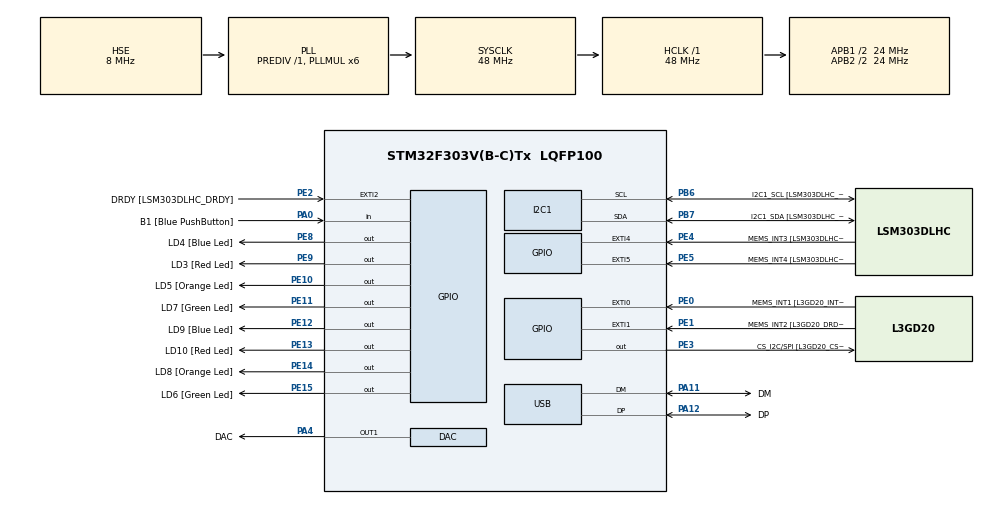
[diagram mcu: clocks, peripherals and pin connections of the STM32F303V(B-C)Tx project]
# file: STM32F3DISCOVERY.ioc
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ADC1.Channel-0\#ChannelRegularConversion=ADC_CHANNEL_TEMPSENSOR
ADC1.ClockPrescaler=ADC_CLOCK_SYNC_PCLK_DIV4
ADC1.NbrOfConversionFlag=1
ADC1.Offset-0\#ChannelRegularConversion=0
ADC1.OffsetNumber-0\#ChannelRegularConversion=ADC_OFFSET_NONE
ADC1.Overrun=ADC_OVR_DATA_OVERWRITTEN
ADC1.Rank-0\#ChannelRegularConversion=1
ADC1.SamplingTime-0\#ChannelRegularConversion=ADC_SAMPLETIME_1CYCLE_5
ADC1.master=1
FREERTOS.Tasks01=defaultTask,0,256,StartDefaultTask,Default
Mcu.Family=STM32F3
Mcu.Name=STM32F303V(B-C)Tx
Mcu.Package=LQFP100
NVIC.PriorityGroup=NVIC_PRIORITYGROUP_4
NVIC.TIM1_UP_TIM16_IRQn=true\:0\:0\:false\:false\:true\:false
NVIC.TimeBase=TIM1_UP_TIM16_IRQn
NVIC.TimeBaseIP=TIM1
NVIC.USB_LP_CAN_RX0_IRQn=true\:0\:0\:false\:false\:true\:false
PA0.GPIO_Label=B1 [Blue PushButton]
PA0.GPIO_Mode=GPIO_MODE_INPUT
PA0.GPIO_PuPd=GPIO_NOPULL
PA0.Signal=GPIO_Input
PA11.GPIO_Label=DM
PA11.Mode=Device
PA11.Signal=USB_DM
PA12.GPIO_Label=DP
PA12.Mode=Device
PA12.Signal=USB_DP
PA13.GPIO_Label=SWDIO
PA13.Mode=Serial_Wire
PA13.Signal=SYS_JTMS-SWDIO
PA14.GPIO_Label=SWCLK
PA14.Mode=Serial_Wire
PA14.Signal=SYS_JTCK-SWCLK
PA4.GPIO_Label=DAC
PA4.Signal=COMP_DAC1_group
PA5.GPIO_Label=SPI1_SCK [L3GD20_SCL/SPC]
PA5.GPIO_Mode=GPIO_MODE_AF_PP
PA5.GPIO_PuPd=GPIO_NOPULL
PA5.GPIO_Speed=GPIO_SPEED_FREQ_LOW
PA5.Signal=SPI1_SCK
PA6.GPIO_Label=SPI1_MISO [L3GD20_SA0/SDO]
PA6.GPIO_Mode=GPIO_MODE_AF_PP
PA6.GPIO_PuPd=GPIO_NOPULL
PA6.GPIO_Speed=GPIO_SPEED_FREQ_LOW
PA6.Signal=SPI1_MISO
PA7.GPIO_Label=SPI1_MISO [L3GD20_SDA/SDI/SDO]
PA7.GPIO_Mode=GPIO_MODE_AF_PP
PA7.GPIO_PuPd=GPIO_NOPULL
PA7.GPIO_Speed=GPIO_SPEED_FREQ_LOW
PA7.Signal=SPI1_MOSI
PB3.GPIO_Label=SWO
PB3.Signal=SYS_JTDO-TRACESWO
PB6.GPIO_FM6=__NULL
PB6.GPIO_Label=I2C1_SCL [LSM303DLHC_SCL]
PB6.GPIO_Mode=GPIO_MODE_AF_OD
PB6.GPIO_PuPd=GPIO_NOPULL
PB6.GPIO_Speed=GPIO_SPEED_FREQ_LOW
PB6.Mode=I2C
PB6.Signal=I2C1_SCL
PB7.GPIO_FM7=__NULL
PB7.GPIO_Label=I2C1_SDA [LSM303DLHC_SDA]
PB7.GPIO_Mode=GPIO_MODE_AF_OD
PB7.GPIO_PuPd=GPIO_NOPULL
PB7.GPIO_Speed=GPIO_SPEED_FREQ_LOW
PB7.Mode=I2C
PB7.Signal=I2C1_SDA
PC14-OSC32_IN.GPIO_Label=OSC32_IN
PC14-OSC32_IN.Mode=LSE-External-Oscillator
PC14-OSC32_IN.Signal=RCC_OSC32_IN
PC15-OSC32_OUT.GPIO_Label=OSC32_OUT
PC15-OSC32_OUT.Mode=LSE-External-Oscillator
PC15-OSC32_OUT.Signal=RCC_OSC32_OUT
PE0.GPIO_Label=MEMS_INT1 [L3GD20_INT1]
PE0.GPIO_ModeDefaultEXTI=GPIO_MODE_EVT_RISING
PE0.GPIO_PuPd=GPIO_NOPULL
PE0.Signal=GPXTI0
PE1.GPIO_Label=MEMS_INT2 [L3GD20_DRDY/INT2]
PE1.GPIO_ModeDefaultEXTI=GPIO_MODE_EVT_RISING
PE1.GPIO_PuPd=GPIO_NOPULL
PE1.Signal=GPXTI1
PE10.GPIO_Label=LD5 [Orange Led]
PE10.GPIO_ModeDefaultOutputPP=GPIO_MODE_OUTPUT_PP
PE10.GPIO_PuPd=GPIO_NOPULL
PE10.GPIO_Speed=GPIO_SPEED_FREQ_LOW
PE10.Signal=GPIO_Output
PE11.GPIO_Label=LD7 [Green Led]
PE11.GPIO_ModeDefaultOutputPP=GPIO_MODE_OUTPUT_PP
PE11.GPIO_PuPd=GPIO_NOPULL
PE11.GPIO_Speed=GPIO_SPEED_FREQ_LOW
PE11.Signal=GPIO_Output
PE12.GPIO_Label=LD9 [Blue Led]
PE12.GPIO_ModeDefaultOutputPP=GPIO_MODE_OUTPUT_PP
PE12.GPIO_PuPd=GPIO_NOPULL
PE12.GPIO_Speed=GPIO_SPEED_FREQ_LOW
PE12.Signal=GPIO_Output
PE13.GPIO_Label=LD10 [Red Led]
PE13.GPIO_ModeDefaultOutputPP=GPIO_MODE_OUTPUT_PP
PE13.GPIO_PuPd=GPIO_NOPULL
PE13.GPIO_Speed=GPIO_SPEED_FREQ_LOW
PE13.Signal=GPIO_Output
PE14.GPIO_Label=LD8 [Orange Led]
PE14.GPIO_ModeDefaultOutputPP=GPIO_MODE_OUTPUT_PP
PE14.GPIO_PuPd=GPIO_NOPULL
PE14.GPIO_Speed=GPIO_SPEED_FREQ_LOW
PE14.Signal=GPIO_Output
PE15.GPIO_Label=LD6 [Green Led]
PE15.GPIO_ModeDefaultOutputPP=GPIO_MODE_OUTPUT_PP
PE15.GPIO_PuPd=GPIO_NOPULL
PE15.GPIO_Speed=GPIO_SPEED_FREQ_LOW
PE15.Signal=GPIO_Output
PE2.GPIO_Label=DRDY [LSM303DLHC_DRDY]
PE2.GPIO_ModeDefaultEXTI=GPIO_MODE_EVT_RISING
PE2.GPIO_PuPd=GPIO_NOPULL
PE2.Signal=GPXTI2
PE3.GPIO_Label=CS_I2C/SPI [L3GD20_CS_I2C/SPI]
PE3.GPIO_ModeDefaultOutputPP=GPIO_MODE_OUTPUT_PP
PE3.GPIO_PuPd=GPIO_NOPULL
PE3.GPIO_Speed=GPIO_SPEED_FREQ_LOW
PE3.Signal=GPIO_Output
PE4.GPIO_Label=MEMS_INT3 [LSM303DLHC_INT1]
PE4.GPIO_ModeDefaultEXTI=GPIO_MODE_EVT_RISING
PE4.GPIO_PuPd=GPIO_NOPULL
PE4.Signal=GPXTI4
PE5.GPIO_Label=MEMS_INT4 [LSM303DLHC_INT2]
PE5.GPIO_ModeDefaultEXTI=GPIO_MODE_EVT_RISING
PE5.GPIO_PuPd=GPIO_NOPULL
PE5.Signal=GPXTI5
PE8.GPIO_Label=LD4 [Blue Led]
PE8.GPIO_ModeDefaultOutputPP=GPIO_MODE_OUTPUT_PP
PE8.GPIO_PuPd=GPIO_NOPULL
PE8.GPIO_Speed=GPIO_SPEED_FREQ_LOW
PE8.Signal=GPIO_Output
PE9.GPIO_Label=LD3 [Red Led]
PE9.GPIO_ModeDefaultOutputPP=GPIO_MODE_OUTPUT_PP
PE9.GPIO_PuPd=GPIO_NOPULL
PE9.GPIO_Speed=GPIO_SPEED_FREQ_LOW
PE9.Signal=GPIO_Output
PF0-OSC_IN.GPIO_Label=OSC_IN
PF0-OSC_IN.Mode=HSE-External-Oscillator
PF0-OSC_IN.Signal=RCC_OSC_IN
PF1-OSC_OUT.GPIO_Label=OSC_OUT
PF1-OSC_OUT.Mode=HSE-External-Oscillator
PF1-OSC_OUT.Signal=RCC_OSC_OUT
ProjectManager.HeapSize=0x200
ProjectManager.StackSize=0x400
ProjectManager.TargetToolchain=TrueSTUDIO
RCC.AHBFreq_Value=48000000
RCC.APB1CLKDivider=RCC_HCLK_DIV2
RCC.APB1Freq_Value=24000000
RCC.APB1TimFreq_Value=48000000
RCC.APB2CLKDivider=RCC_HCLK_DIV2
RCC.APB2Freq_Value=24000000
RCC.APB2TimFreq_Value=48000000
RCC.CortexFreq_Value=48000000
RCC.HCLKFreq_Value=48000000
RCC.HSE_VALUE=8000000
RCC.HSI_VALUE=8000000
RCC.PLLMUL=RCC_PLL_MUL6
RCC.SYSCLKFreq_VALUE=48000000
RCC.SYSCLKSourceVirtual=RCC_SYSCLKSOURCE_PLLCLK
RCC.USBFreq_Value=48000000
RCC.VDD_VALUE=3
SH.COMP_DAC1_group.0=DAC_OUT1,DAC_OUT1
USB_DEVICE.CLASS_NAME_FS=CDC
USB_DEVICE.USBD_HandleTypeDef=hUsbDeviceFS
USB_DEVICE.VirtualMode=Cdc
USB_DEVICE.VirtualModeFS=Cdc_FS
VP_ADC1_TempSens_Input.Mode=IN-TempSens
VP_CRC_VS_CRC.Mode=CRC_Activate
VP_FREERTOS_VS_ENABLE.Mode=Enabled
VP_IWDG_VS_IWDG.Mode=IWDG_Activate
VP_SYS_VS_tim1.Mode=TIM1
VP_USB_DEVICE_VS_USB_DEVICE_CDC_FS.Mode=CDC_FS
VP_WWDG_VS_WWDG.Mode=WWDG_Activate
board=STM32F3DISCOVERY

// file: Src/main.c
/**
  ******************************************************************************
  * File Name          : main.c
  * Description        : Main program body
  ******************************************************************************
  *
  * COPYRIGHT(c) 2016 STMicroelectronics
  *
  * Redistribution and use in source and binary forms, with or without modification,
  * are permitted provided that the following conditions are met:
  *   1. Redistributions of source code must retain the above copyright notice,
  *      this list of conditions and the following disclaimer.
  *   2. Redistributions in binary form must reproduce the above copyright notice,
  *      this list of conditions and the following disclaimer in the documentation
  *      and/or other materials provided with the distribution.
  *   3. Neither the name of STMicroelectronics nor the names of its contributors
  *      may be used to endorse or promote products derived from this software
  *      without specific prior written permission.
  *
  * THIS SOFTWARE IS PROVIDED BY THE COPYRIGHT HOLDERS AND CONTRIBUTORS "AS IS"
  * AND ANY EXPRESS OR IMPLIED WARRANTIES, INCLUDING, BUT NOT LIMITED TO, THE
  * IMPLIED WARRANTIES OF MERCHANTABILITY AND FITNESS FOR A PARTICULAR PURPOSE ARE
  * DISCLAIMED. IN NO EVENT SHALL THE COPYRIGHT HOLDER OR CONTRIBUTORS BE LIABLE
  * FOR ANY DIRECT, INDIRECT, INCIDENTAL, SPECIAL, EXEMPLARY, OR CONSEQUENTIAL
  * DAMAGES (INCLUDING, BUT NOT LIMITED TO, PROCUREMENT OF SUBSTITUTE GOODS OR
  * SERVICES; LOSS OF USE, DATA, OR PROFITS; OR BUSINESS INTERRUPTION) HOWEVER
  * CAUSED AND ON ANY THEORY OF LIABILITY, WHETHER IN CONTRACT, STRICT LIABILITY,
  * OR TORT (INCLUDING NEGLIGENCE OR OTHERWISE) ARISING IN ANY WAY OUT OF THE USE
  * OF THIS SOFTWARE, EVEN IF ADVISED OF THE POSSIBILITY OF SUCH DAMAGE.
  *
  ******************************************************************************
  */
#include "stm32f3xx_hal.h"
#include "cmsis_os.h"
#include "adc.h"
#include "crc.h"
#include "dac.h"
#include "i2c.h"
#include "iwdg.h"
#include "usb_device.h"
#include "wwdg.h"
#include "gpio.h"

/* USER CODE BEGIN PV */
/* Private variables ---------------------------------------------------------*/

/* USER CODE END PV */

void SystemClock_Config(void);
void Error_Handler(void);
void MX_FREERTOS_Init(void);

/* USER CODE BEGIN PFP */
/* Private function prototypes -----------------------------------------------*/

/* USER CODE END PFP */

int main(void)
{
  /* MCU Configuration----------------------------------------------------------*/
  /* Reset of all peripherals, Initializes the Flash interface and the Systick. */
  HAL_Init();
  /* Configure the system clock */
  SystemClock_Config();
  /* Initialize all configured peripherals */
  MX_GPIO_Init();
  MX_ADC1_Init();
  MX_DAC_Init();
  MX_I2C1_Init();
  MX_CRC_Init();
  //MX_IWDG_Init();
  //MX_WWDG_Init();
  /* Call init function for freertos objects (in freertos.c) */
  MX_FREERTOS_Init();
  /* Start scheduler */
  osKernelStart();

  /* We should never get here as control is now taken by the scheduler */

  /* Infinite loop */
  while(1)
  {
  }
}

/** System Clock Configuration
*/
void SystemClock_Config(void)
{
  RCC_OscInitTypeDef RCC_OscInitStruct;
  RCC_ClkInitTypeDef RCC_ClkInitStruct;
  RCC_PeriphCLKInitTypeDef PeriphClkInit;
  RCC_OscInitStruct.OscillatorType = RCC_OSCILLATORTYPE_HSI|RCC_OSCILLATORTYPE_LSI
                                     |RCC_OSCILLATORTYPE_HSE;
  RCC_OscInitStruct.HSEState = RCC_HSE_ON;
  RCC_OscInitStruct.HSEPredivValue = RCC_HSE_PREDIV_DIV1;
  RCC_OscInitStruct.HSIState = RCC_HSI_ON;
  RCC_OscInitStruct.HSICalibrationValue = 16;
  RCC_OscInitStruct.LSIState = RCC_LSI_ON;
  RCC_OscInitStruct.PLL.PLLState = RCC_PLL_ON;
  RCC_OscInitStruct.PLL.PLLSource = RCC_PLLSOURCE_HSE;
  RCC_OscInitStruct.PLL.PLLMUL = RCC_PLL_MUL6;

  if(HAL_RCC_OscConfig(&RCC_OscInitStruct) != HAL_OK)
  {
    Error_Handler();
  }

  RCC_ClkInitStruct.ClockType = RCC_CLOCKTYPE_HCLK|RCC_CLOCKTYPE_SYSCLK
                                |RCC_CLOCKTYPE_PCLK1|RCC_CLOCKTYPE_PCLK2;
  RCC_ClkInitStruct.SYSCLKSource = RCC_SYSCLKSOURCE_PLLCLK;
  RCC_ClkInitStruct.AHBCLKDivider = RCC_SYSCLK_DIV1;
  RCC_ClkInitStruct.APB1CLKDivider = RCC_HCLK_DIV2;
  RCC_ClkInitStruct.APB2CLKDivider = RCC_HCLK_DIV2;

  if(HAL_RCC_ClockConfig(&RCC_ClkInitStruct, FLASH_LATENCY_1) != HAL_OK)
  {
    Error_Handler();
  }

  PeriphClkInit.PeriphClockSelection = RCC_PERIPHCLK_USB|RCC_PERIPHCLK_I2C1
                                       |RCC_PERIPHCLK_ADC12;
  PeriphClkInit.Adc12ClockSelection = RCC_ADC12PLLCLK_DIV1;
  PeriphClkInit.I2c1ClockSelection = RCC_I2C1CLKSOURCE_HSI;
  PeriphClkInit.USBClockSelection = RCC_USBCLKSOURCE_PLL;

  if(HAL_RCCEx_PeriphCLKConfig(&PeriphClkInit) != HAL_OK)
  {
    Error_Handler();
  }

  HAL_SYSTICK_Config(HAL_RCC_GetHCLKFreq()/1000);
  HAL_SYSTICK_CLKSourceConfig(SYSTICK_CLKSOURCE_HCLK);
  /* SysTick_IRQn interrupt configuration */
  HAL_NVIC_SetPriority(SysTick_IRQn, 6, 0);
}

void HAL_TIM_PeriodElapsedCallback(TIM_HandleTypeDef *htim)
{
  if(htim->Instance == TIM1)
  {
    HAL_IncTick();
  }

}

void Error_Handler(void)
{
  /* USER CODE BEGIN Error_Handler */
  #ifdef _DEBUG
  __asm("BKPT #0\n") ; // Break into the debugger
  #endif

  /* User can add his own implementation to report the HAL error return state */
  while(1)
  {
  }

  /* USER CODE END Error_Handler */
}

#ifdef USE_FULL_ASSERT

/**
   * @brief Reports the name of the source file and the source line number
   * where the assert_param error has occurred.
   * @param file: pointer to the source file name
   * @param line: assert_param error line source number
   * @retval None
   */
void assert_failed(uint8_t* file, uint32_t line)
{
  /* USER CODE BEGIN 6 */
  #ifdef _DEBUG
  __asm("BKPT #0\n") ; // Break into the debugger
  #endif
  /* User can add his own implementation to report the file name and line number,
    ex: printf("Wrong parameters value: file %s on line %d\r\n", file, line) */
  /* USER CODE END 6 */
}

#endif

/************************ (C) COPYRIGHT STMicroelectronics *****END OF FILE****/

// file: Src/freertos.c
/**
  ******************************************************************************
  * File Name          : freertos.c
  * Description        : Code for freertos applications
  ******************************************************************************
  *
  * COPYRIGHT(c) 2016 STMicroelectronics
  *
  * Redistribution and use in source and binary forms, with or without modification,
  * are permitted provided that the following conditions are met:
  *   1. Redistributions of source code must retain the above copyright notice,
  *      this list of conditions and the following disclaimer.
  *   2. Redistributions in binary form must reproduce the above copyright notice,
  *      this list of conditions and the following disclaimer in the documentation
  *      and/or other materials provided with the distribution.
  *   3. Neither the name of STMicroelectronics nor the names of its contributors
  *      may be used to endorse or promote products derived from this software
  *      without specific prior written permission.
  *
  * THIS SOFTWARE IS PROVIDED BY THE COPYRIGHT HOLDERS AND CONTRIBUTORS "AS IS"
  * AND ANY EXPRESS OR IMPLIED WARRANTIES, INCLUDING, BUT NOT LIMITED TO, THE
  * IMPLIED WARRANTIES OF MERCHANTABILITY AND FITNESS FOR A PARTICULAR PURPOSE ARE
  * DISCLAIMED. IN NO EVENT SHALL THE COPYRIGHT HOLDER OR CONTRIBUTORS BE LIABLE
  * FOR ANY DIRECT, INDIRECT, INCIDENTAL, SPECIAL, EXEMPLARY, OR CONSEQUENTIAL
  * DAMAGES (INCLUDING, BUT NOT LIMITED TO, PROCUREMENT OF SUBSTITUTE GOODS OR
  * SERVICES; LOSS OF USE, DATA, OR PROFITS; OR BUSINESS INTERRUPTION) HOWEVER
  * CAUSED AND ON ANY THEORY OF LIABILITY, WHETHER IN CONTRACT, STRICT LIABILITY,
  * OR TORT (INCLUDING NEGLIGENCE OR OTHERWISE) ARISING IN ANY WAY OUT OF THE USE
  * OF THIS SOFTWARE, EVEN IF ADVISED OF THE POSSIBILITY OF SUCH DAMAGE.
  *
  ******************************************************************************
  */

#include "FreeRTOS.h"
#include "task.h"
#include "cmsis_os.h"

/* USER CODE BEGIN Includes */
#include "command.h"
/* USER CODE END Includes */

osThreadId defaultTaskHandle;

void StartDefaultTask(void const * argument);

extern void MX_USB_DEVICE_Init(void);
void MX_FREERTOS_Init(void); /* (MISRA C 2004 rule 8.1) */

/* Hook prototypes */

/* Init FreeRTOS */

void MX_FREERTOS_Init(void)
{
  /* USER CODE BEGIN RTOS_SEMAPHORES */
  /* add semaphores, ... */
  cmd_config();
  /* USER CODE END RTOS_SEMAPHORES */
  /* Create the thread(s) */
  /* definition and creation of defaultTask */
  osThreadDef(defaultTask, StartDefaultTask, osPriorityNormal, 0, 256);
  defaultTaskHandle = osThreadCreate(osThread(defaultTask), NULL);
}

/* StartDefaultTask function */
void StartDefaultTask(void const * argument)
{
  uint32_t previousWakeTime ;
  previousWakeTime = osKernelSysTick();
  osDelayUntil (&previousWakeTime, 30);
  /* init code for USB_DEVICE */
  MX_USB_DEVICE_Init();
  /* USER CODE BEGIN StartDefaultTask */

  previousWakeTime = osKernelSysTick();
  osDelayUntil (&previousWakeTime, 350);

  /* Infinite loop */
  cmd_loop();
  /* USER CODE END StartDefaultTask */
}

/************************ (C) COPYRIGHT STMicroelectronics *****END OF FILE****/
